# STM32H743V register map
File version: 2.4
CPU: CM7 r0p1, little endian, MPU, FPU, 4 interrupt priority bits
Registers are 32-bit, read-write, reset 0x0 unless marked. A register's access mark holds for its fields unless they carry their own. Offsets are from the block's base; [hi:lo] are bit positions; {n}, {i} and the like mark numbered series; 'fields as' and 'values as' point back to an identical list.

## Ethernet_MAC — Ethernet: media access control (MAC)
Base 0x40028000
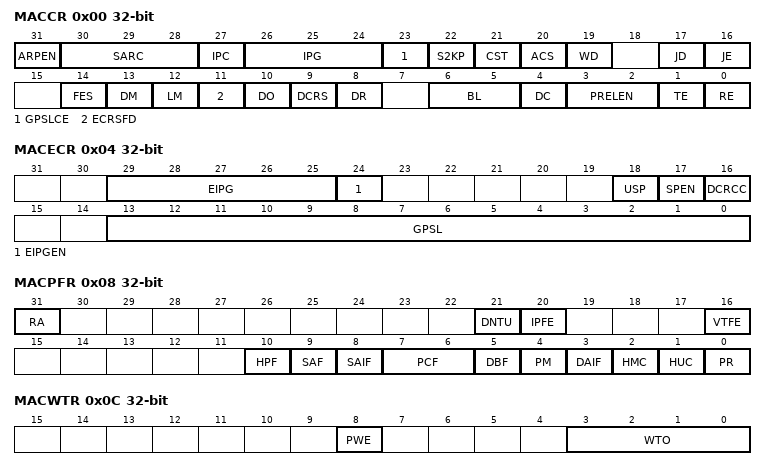
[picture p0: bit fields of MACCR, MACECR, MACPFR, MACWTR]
0x00 MACCR — Operating mode configuration register
  [31] ARPEN — ARP Offload Enable
  [30:28] SARC — Source Address Insertion or Replacement Control
  [27] IPC — Checksum Offload
  [26:24] IPG — Inter-Packet Gap
  [23] GPSLCE — Giant Packet Size Limit Control Enable
  [22] S2KP — IEEE 802.3as Support for 2K Packets
  [21] CST — CRC stripping for Type packets
  [20] ACS — Automatic Pad or CRC Stripping
  [19] WD — Watchdog Disable
  [17] JD — Jabber Disable
  [16] JE — Jumbo Packet Enable
  [14] FES — MAC Speed
  [13] DM — Duplex Mode
  [12] LM — Loopback Mode
  [11] ECRSFD — Enable Carrier Sense Before Transmission in Full-Duplex Mode
  [10] DO — Disable Receive Own
  [9] DCRS — Disable Carrier Sense During Transmission
  [8] DR — Disable Retry
  [6:5] BL — Back-Off Limit
  [4] DC — Deferral Check
  [3:2] PRELEN — Preamble Length for Transmit Packets
  [1] TE — Transmitter Enable
  [0] RE — Receiver Enable
0x04 MACECR — Extended operating mode configuration register
  [29:25] EIPG — Extended Inter-Packet Gap
  [24] EIPGEN — Extended Inter-Packet Gap Enable
  [18] USP — Unicast Slow Protocol Packet Detect
  [17] SPEN — Slow Protocol Detection Enable
  [16] DCRCC — Disable CRC Checking for Received Packets
  [13:0] GPSL — Giant Packet Size Limit
0x08 MACPFR — Packet filtering control register
  [31] RA — Receive All
  [21] DNTU — Drop Non-TCP/UDP over IP Packets
  [20] IPFE — Layer 3 and Layer 4 Filter Enable
  [16] VTFE — VLAN Tag Filter Enable
  [10] HPF — Hash or Perfect Filter
  [9] SAF — Source Address Filter Enable
  [8] SAIF — SA Inverse Filtering
  [7:6] PCF — Pass Control Packets
  [5] DBF — Disable Broadcast Packets
  [4] PM — Pass All Multicast
  [3] DAIF — DA Inverse Filtering
  [2] HMC — Hash Multicast
  [1] HUC — Hash Unicast
  [0] PR — Promiscuous Mode
0x0C MACWTR — Watchdog timeout register
  [8] PWE — Programmable Watchdog Enable
  [3:0] WTO — Watchdog Timeout
0x10 MACHT0R — Hash Table 0 register
  [31:0] HT31T0 — MAC Hash Table First 32 Bits
0x14 MACHT1R — Hash Table 1 register
  [31:0] HT63T32 — MAC Hash Table Second 32 Bits
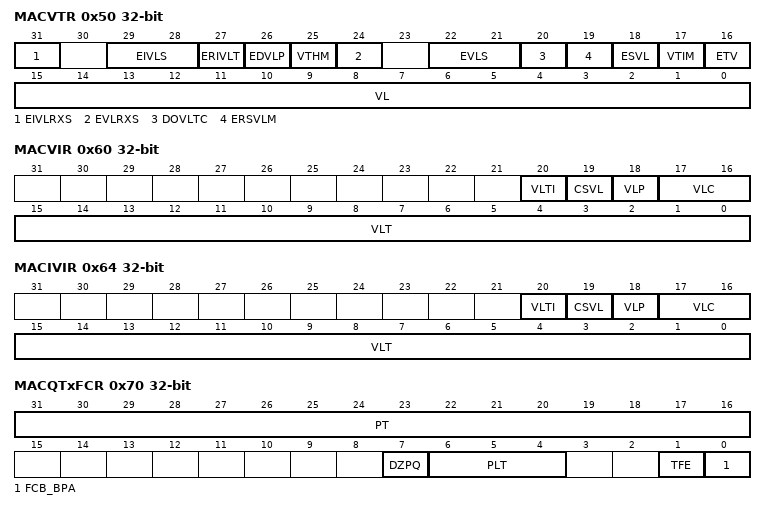
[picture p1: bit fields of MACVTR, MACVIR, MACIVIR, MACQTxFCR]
0x50 MACVTR — VLAN tag register
  [31] EIVLRXS — Enable Inner VLAN Tag in Rx Status
  [29:28] EIVLS — Enable Inner VLAN Tag Stripping on Receive
  [27] ERIVLT — Enable Inner VLAN Tag
  [26] EDVLP — Enable Double VLAN Processing
  [25] VTHM — VLAN Tag Hash Table Match Enable
  [24] EVLRXS — Enable VLAN Tag in Rx status
  [22:21] EVLS — Enable VLAN Tag Stripping on Receive
  [20] DOVLTC — Disable VLAN Type Check
  [19] ERSVLM — Enable Receive S-VLAN Match
  [18] ESVL — Enable S-VLAN
  [17] VTIM — VLAN Tag Inverse Match Enable
  [16] ETV — Enable 12-Bit VLAN Tag Comparison
  [15:0] VL — VLAN Tag Identifier for Receive Packets
0x58 MACVHTR — VLAN Hash table register
  [15:0] VLHT — VLAN Hash Table
0x60 MACVIR — VLAN inclusion register
  [20] VLTI — VLAN Tag Input
  [19] CSVL — C-VLAN or S-VLAN
  [18] VLP — VLAN Priority Control
  [17:16] VLC — VLAN Tag Control in Transmit Packets
  [15:0] VLT — VLAN Tag for Transmit Packets
0x64 MACIVIR — Inner VLAN inclusion register
  fields as MACVIR
0x70 MACQTxFCR — Tx Queue flow control register
  [31:16] PT — Pause Time
  [7] DZPQ — Disable Zero-Quanta Pause
  [6:4] PLT — Pause Low Threshold
  [1] TFE — Transmit Flow Control Enable
  [0] FCB_BPA — Flow Control Busy or Backpressure Activate
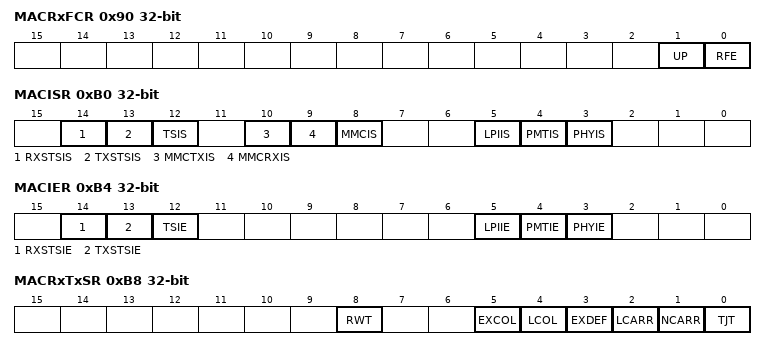
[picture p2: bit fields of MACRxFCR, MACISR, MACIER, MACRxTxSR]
0x90 MACRxFCR — Rx flow control register
  [1] UP — Unicast Pause Packet Detect
  [0] RFE — Receive Flow Control Enable
0xB0 MACISR ro — Interrupt status register
  [14] RXSTSIS — Receive Status Interrupt
  [13] TXSTSIS — Transmit Status Interrupt
  [12] TSIS — Timestamp Interrupt Status
  [10] MMCTXIS — MMC Transmit Interrupt Status
  [9] MMCRXIS — MMC Receive Interrupt Status
  [8] MMCIS — MMC Interrupt Status
  [5] LPIIS — LPI Interrupt Status
  [4] PMTIS — PMT Interrupt Status
  [3] PHYIS — PHY Interrupt
0xB4 MACIER — Interrupt enable register
  [14] RXSTSIE — Receive Status Interrupt Enable
  [13] TXSTSIE — Transmit Status Interrupt Enable
  [12] TSIE — Timestamp Interrupt Enable
  [5] LPIIE — LPI Interrupt Enable
  [4] PMTIE — PMT Interrupt Enable
  [3] PHYIE — PHY Interrupt Enable
0xB8 MACRxTxSR ro — Rx Tx status register
  [8] RWT — Receive Watchdog Timeout
  [5] EXCOL — Excessive Collisions
  [4] LCOL — Late Collision
  [3] EXDEF — Excessive Deferral
  [2] LCARR — Loss of Carrier
  [1] NCARR — No Carrier
  [0] TJT — Transmit Jabber Timeout
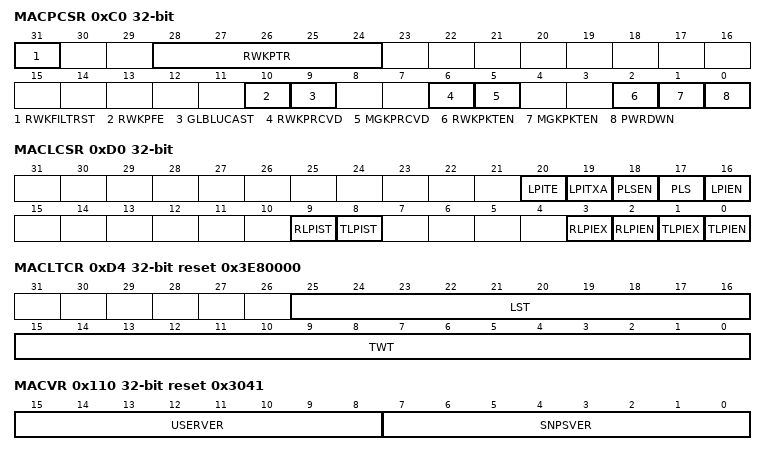
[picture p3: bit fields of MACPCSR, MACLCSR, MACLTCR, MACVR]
0xC0 MACPCSR access per field — PMT control status register
  [31] RWKFILTRST rw — Remote wakeup Packet Filter Register Pointer Reset
  [28:24] RWKPTR rw — Remote wakeup FIFO Pointer
  [10] RWKPFE rw — Remote wakeup Packet Forwarding Enable
  [9] GLBLUCAST rw — Global Unicast
  [6] RWKPRCVD ro — Remote wakeup Packet Received
  [5] MGKPRCVD ro — Magic Packet Received
  [2] RWKPKTEN rw — Remote wakeup Packet Enable
  [1] MGKPKTEN rw — Magic Packet Enable
  [0] PWRDWN rw — Power Down
0xC4 MACRWKPFR — Remove wakeup packet filter register
  [31:0] MACRWKPFR — Remote wakeup packet filter
0xD0 MACLCSR access per field — LPI control status register
  [20] LPITE rw — LPI Timer Enable
  [19] LPITXA rw — LPI Tx Automate
  [18] PLSEN rw — PHY Link Status Enable
  [17] PLS rw — PHY Link Status
  [16] LPIEN rw — LPI Enable
  [9] RLPIST ro — Receive LPI State
  [8] TLPIST ro — Transmit LPI State
  [3] RLPIEX ro — Receive LPI Exit
  [2] RLPIEN ro — Receive LPI Entry
  [1] TLPIEX ro — Transmit LPI Exit
  [0] TLPIEN ro — Transmit LPI Entry
0xD4 MACLTCR reset 0x3E80000 — LPI timers control register
  [25:16] LST — LPI LS Timer
  [15:0] TWT — LPI TW Timer
0xD8 MACLETR — LPI entry timer register
  [19:3] LPIET — LPI Entry Timer
0xDC MAC1USTCR — 1-microsecond-tick counter register
  [11:0] TIC_1US_CNTR — 1 µs tick Counter
0x110 MACVR ro reset 0x3041 — Version register
  [15:8] USERVER — ST-defined version
  [7:0] SNPSVER — IP version
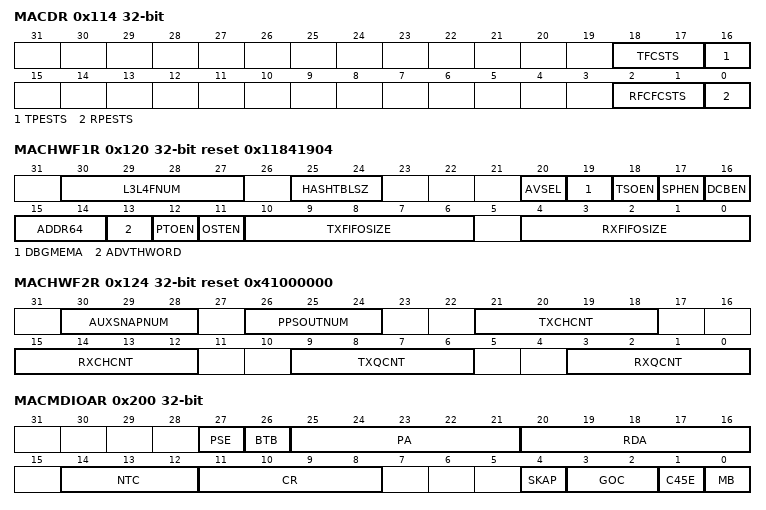
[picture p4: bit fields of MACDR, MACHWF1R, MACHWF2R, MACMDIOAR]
0x114 MACDR ro — Debug register
  [18:17] TFCSTS — MAC Transmit Packet Controller Status
  [16] TPESTS — MAC MII Transmit Protocol Engine Status
  [2:1] RFCFCSTS — MAC Receive Packet Controller FIFO Status
  [0] RPESTS — MAC MII Receive Protocol Engine Status
0x120 MACHWF1R ro reset 0x11841904 — HW feature 1 register
  [30:27] L3L4FNUM — Total number of L3 or L4 Filters
  [25:24] HASHTBLSZ — Hash Table Size
  [20] AVSEL — AV Feature Enable
  [19] DBGMEMA — DMA Debug Registers Enable
  [18] TSOEN — TCP Segmentation Offload Enable
  [17] SPHEN — Split Header Feature Enable
  [16] DCBEN — DCB Feature Enable
  [15:14] ADDR64 — Address width
  [13] ADVTHWORD — IEEE 1588 High Word Register Enable
  [12] PTOEN — PTP Offload Enable
  [11] OSTEN — One-Step Timestamping Enable
  [10:6] TXFIFOSIZE — MTL Transmit FIFO Size
  [4:0] RXFIFOSIZE — MTL Receive FIFO Size
0x124 MACHWF2R ro reset 0x41000000 — HW feature 2 register
  [30:28] AUXSNAPNUM — Number of Auxiliary Snapshot Inputs
  [26:24] PPSOUTNUM — Number of PPS Outputs
  [21:18] TXCHCNT — Number of DMA Transmit Channels
  [15:12] RXCHCNT — Number of DMA Receive Channels
  [9:6] TXQCNT — Number of MTL Transmit Queues
  [3:0] RXQCNT — Number of MTL Receive Queues
0x200 MACMDIOAR — MDIO address register
  [27] PSE — Preamble Suppression Enable
  [26] BTB — Back to Back transactions
  [25:21] PA — Physical Layer Address
  [20:16] RDA — Register/Device Address
  [14:12] NTC — Number of Training Clocks
  [11:8] CR — CSR Clock Range
  [4] SKAP — Skip Address Packet
  [3:2] GOC — MII Operation Command
  [1] C45E — Clause 45 PHY Enable
  [0] MB — MII Busy
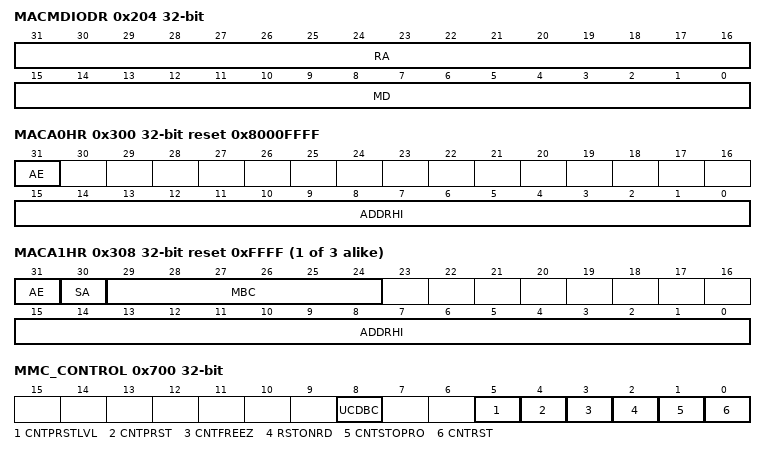
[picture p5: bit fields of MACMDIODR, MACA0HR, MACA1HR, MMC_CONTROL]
0x204 MACMDIODR — MDIO data register
  [31:16] RA — Register Address
  [15:0] MD — MII Data
0x300 MACA0HR access per field reset 0x8000FFFF — Address 0 high register
  [31] AE ro — Address Enable
  [15:0] ADDRHI rw — MAC Address0[47:32]
{0x304+8i} MACA{i}LR reset 0xFFFFFFFF (i=0..3) — Address {i} low register
  [31:0] ADDRLO — MAC Address {i} [31:0]
{0x300+8i} MACA{i}HR reset 0xFFFF (i=1..3) — Address {i} high register
  [31] AE — Address Enable
  [30] SA — Source Address
  [29:24] MBC — Mask Byte Control
  [15:0] ADDRHI — MAC Address{i} [47:32]
0x700 MMC_CONTROL
  [8] UCDBC — Update MMC Counters for Dropped Broadcast Packets
  [5] CNTPRSTLVL — Full-Half Preset
  [4] CNTPRST — Counters Preset
  [3] CNTFREEZ — MMC Counter Freeze
  [2] RSTONRD — Reset on Read
  [1] CNTSTOPRO — Counter Stop Rollover
  [0] CNTRST — Counters Reset
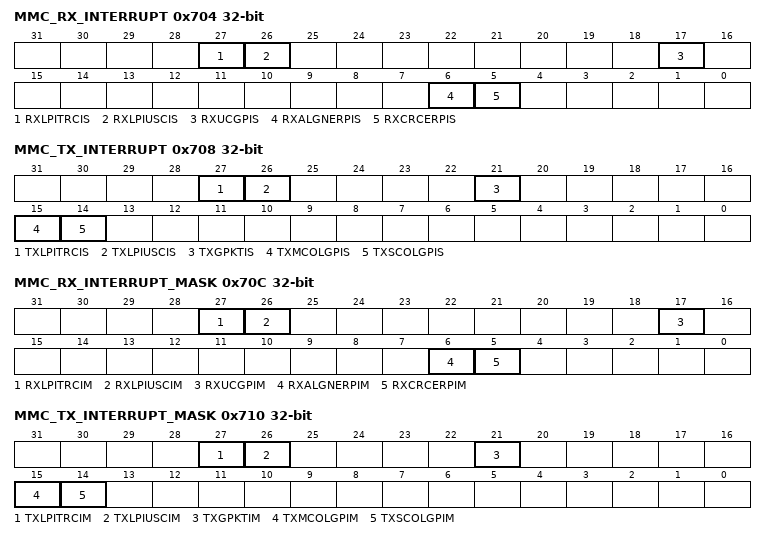
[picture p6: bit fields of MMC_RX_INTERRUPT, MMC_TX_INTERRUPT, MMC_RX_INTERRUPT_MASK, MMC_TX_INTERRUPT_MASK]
0x704 MMC_RX_INTERRUPT ro
  [27] RXLPITRCIS — MMC Receive LPI transition counter interrupt status
  [26] RXLPIUSCIS — MMC Receive LPI microsecond counter interrupt status
  [17] RXUCGPIS — MMC Receive Unicast Good Packet Counter Interrupt Status
  [6] RXALGNERPIS — MMC Receive Alignment Error Packet Counter Interrupt Status
  [5] RXCRCERPIS — MMC Receive CRC Error Packet Counter Interrupt Status
0x708 MMC_TX_INTERRUPT ro
  [27] TXLPITRCIS — MMC Transmit LPI transition counter interrupt status
  [26] TXLPIUSCIS — MMC Transmit LPI microsecond counter interrupt status
  [21] TXGPKTIS — MMC Transmit Good Packet Counter Interrupt Status
  [15] TXMCOLGPIS — MMC Transmit Multiple Collision Good Packet Counter Interrupt Status
  [14] TXSCOLGPIS — MMC Transmit Single Collision Good Packet Counter Interrupt Status
0x70C MMC_RX_INTERRUPT_MASK
  [27] RXLPITRCIM — MMC Receive LPI transition counter interrupt Mask
  [26] RXLPIUSCIM — MMC Receive LPI microsecond counter interrupt Mask
  [17] RXUCGPIM — MMC Receive Unicast Good Packet Counter Interrupt Mask
  [6] RXALGNERPIM — MMC Receive Alignment Error Packet Counter Interrupt Mask
  [5] RXCRCERPIM — MMC Receive CRC Error Packet Counter Interrupt Mask
0x710 MMC_TX_INTERRUPT_MASK
  [27] TXLPITRCIM — MMC Transmit LPI transition counter interrupt Mask
  [26] TXLPIUSCIM — MMC Transmit LPI microsecond counter interrupt Mask
  [21] TXGPKTIM — MMC Transmit Good Packet Counter Interrupt Mask
  [15] TXMCOLGPIM — MMC Transmit Multiple Collision Good Packet Counter Interrupt Mask
  [14] TXSCOLGPIM — MMC Transmit Single Collision Good Packet Counter Interrupt Mask
0x74C TX_SINGLE_COLLISION_GOOD_PACKETS ro
  [31:0] TXSNGLCOLG — Tx Single Collision Good Packets
0x750 TX_MULTIPLE_COLLISION_GOOD_PACKETS ro
  [31:0] TXMULTCOLG — Tx Multiple Collision Good Packets
0x768 TX_PACKET_COUNT_GOOD ro
  [31:0] TXPKTG — Tx Packet Count Good
0x794 RX_CRC_ERROR_PACKETS ro
  [31:0] RXCRCERR — Rx CRC Error Packets
0x798 RX_ALIGNMENT_ERROR_PACKETS ro
  [31:0] RXALGNERR — Rx Alignment Error Packets
0x7C4 RX_UNICAST_PACKETS_GOOD ro
  [31:0] RXUCASTG — Rx Unicast Packets Good
0x7EC TX_LPI_USEC_CNTR ro — Tx LPI microsecond timer register
  [31:0] TXLPIUSC — Tx LPI Microseconds Counter
0x7F0 TX_LPI_TRAN_CNTR ro — Tx LPI transition counter register
  [31:0] TXLPITRC — Tx LPI Transition counter
0x7F4 RX_LPI_USEC_CNTR ro — Rx LPI microsecond counter register
  [31:0] RXLPIUSC — Rx LPI Microseconds Counter
0x7F8 RX_LPI_TRAN_CNTR ro — Rx LPI transition counter register
  [31:0] RXLPITRC — Rx LPI Transition counter
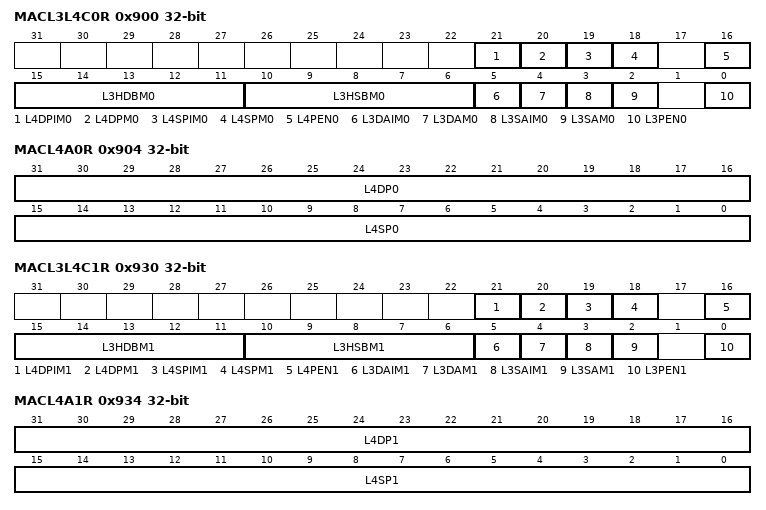
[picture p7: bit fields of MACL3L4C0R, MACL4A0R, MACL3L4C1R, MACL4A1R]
0x900 MACL3L4C0R — L3 and L4 control 0 register
  [21] L4DPIM0 — Layer 4 Destination Port Inverse Match Enable
  [20] L4DPM0 — Layer 4 Destination Port Match Enable
  [19] L4SPIM0 — Layer 4 Source Port Inverse Match Enable
  [18] L4SPM0 — Layer 4 Source Port Match Enable
  [16] L4PEN0 — Layer 4 Protocol Enable
  [15:11] L3HDBM0 — Layer 3 IP DA Higher Bits Match
  [10:6] L3HSBM0 — Layer 3 IP SA Higher Bits Match
  [5] L3DAIM0 — Layer 3 IP DA Inverse Match Enable
  [4] L3DAM0 — Layer 3 IP DA Match Enable
  [3] L3SAIM0 — Layer 3 IP SA Inverse Match Enable
  [2] L3SAM0 — Layer 3 IP SA Match Enable
  [0] L3PEN0 — Layer 3 Protocol Enable
0x904 MACL4A0R — Layer4 address filter 0 register
  [31:16] L4DP0 — Layer 4 Destination Port Number Field
  [15:0] L4SP0 — Layer 4 Source Port Number Field
0x910 MACL3A00R
  [31:0] L3A00 — Layer 3 Address 0 Field
0x914 MACL3A10R — Layer3 address 1 filter 0 register
  [31:0] L3A10 — Layer 3 Address 1 Field
0x918 MACL3A20 — Layer3 Address 2 filter 0 register
  [31:0] L3A20 — Layer 3 Address 2 Field
0x91C MACL3A30 — Layer3 Address 3 filter 0 register
  [31:0] L3A30 — Layer 3 Address 3 Field
0x930 MACL3L4C1R — L3 and L4 control 1 register
  [21] L4DPIM1 — Layer 4 Destination Port Inverse Match Enable
  [20] L4DPM1 — Layer 4 Destination Port Match Enable
  [19] L4SPIM1 — Layer 4 Source Port Inverse Match Enable
  [18] L4SPM1 — Layer 4 Source Port Match Enable
  [16] L4PEN1 — Layer 4 Protocol Enable
  [15:11] L3HDBM1 — Layer 3 IP DA Higher Bits Match
  [10:6] L3HSBM1 — Layer 3 IP SA Higher Bits Match
  [5] L3DAIM1 — Layer 3 IP DA Inverse Match Enable
  [4] L3DAM1 — Layer 3 IP DA Match Enable
  [3] L3SAIM1 — Layer 3 IP SA Inverse Match Enable
  [2] L3SAM1 — Layer 3 IP SA Match Enable
  [0] L3PEN1 — Layer 3 Protocol Enable
0x934 MACL4A1R — Layer 4 address filter 1 register
  [31:16] L4DP1 — Layer 4 Destination Port Number Field
  [15:0] L4SP1 — Layer 4 Source Port Number Field
0x940 MACL3A01R — Layer3 address 0 filter 1 Register
  [31:0] L3A01 — Layer 3 Address 0 Field
0x944 MACL3A11R — Layer3 address 1 filter 1 register
  [31:0] L3A11 — Layer 3 Address 1 Field
0x948 MACL3A21R — Layer3 address 2 filter 1 Register
  [31:0] L3A21 — Layer 3 Address 2 Field
0x94C MACL3A31R — Layer3 address 3 filter 1 register
  [31:0] L3A31 — Layer 3 Address 3 Field
0xAE0 MACARPAR — ARP address register
  [31:0] ARPPA — ARP Protocol Address
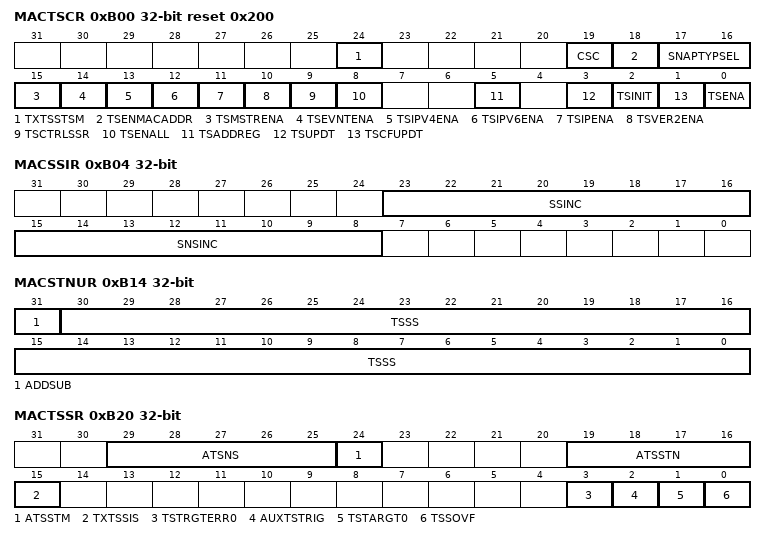
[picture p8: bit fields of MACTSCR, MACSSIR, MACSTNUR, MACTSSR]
0xB00 MACTSCR access per field reset 0x200 — Timestamp control Register
  [24] TXTSSTSM rw — Transmit Timestamp Status Mode
  [19] CSC ro — Enable checksum correction during OST for PTP over UDP/IPv4 packets
  [18] TSENMACADDR rw — Enable MAC Address for PTP Packet Filtering
  [17:16] SNAPTYPSEL rw — Select PTP packets for Taking Snapshots
  [15] TSMSTRENA rw — Enable Snapshot for Messages Relevant to Master
  [14] TSEVNTENA rw — Enable Timestamp Snapshot for Event Messages
  [13] TSIPV4ENA rw — Enable Processing of PTP Packets Sent over IPv4-UDP
  [12] TSIPV6ENA rw — Enable Processing of PTP Packets Sent over IPv6-UDP
  [11] TSIPENA rw — Enable Processing of PTP over Ethernet Packets
  [10] TSVER2ENA rw — Enable PTP Packet Processing for Version 2 Format
  [9] TSCTRLSSR rw — Timestamp Digital or Binary Rollover Control
  [8] TSENALL rw — Enable Timestamp for All Packets
  [5] TSADDREG rw — Update Addend Register
  [3] TSUPDT rw — Update Timestamp
  [2] TSINIT rw — Initialize Timestamp
  [1] TSCFUPDT rw — Fine or Coarse Timestamp Update
  [0] TSENA rw — Enable Timestamp
0xB04 MACSSIR — Sub-second increment register
  [23:16] SSINC — Sub-second Increment Value
  [15:8] SNSINC — Sub-nanosecond Increment Value
0xB08 MACSTSR ro — System time seconds register
  [31:0] TSS — Timestamp Second
0xB0C MACSTNR ro — System time nanoseconds register
  [30:0] TSSS — Timestamp Sub-seconds
0xB10 MACSTSUR — System time seconds update register
  [31:0] TSS — Timestamp Seconds
0xB14 MACSTNUR — System time nanoseconds update register
  [31] ADDSUB — Add or Subtract Time
  [30:0] TSSS — Timestamp Sub-seconds
0xB18 MACTSAR — Timestamp addend register
  [31:0] TSAR — Timestamp Addend Register
0xB20 MACTSSR ro — Timestamp status register
  [29:25] ATSNS — Number of Auxiliary Timestamp Snapshots
  [24] ATSSTM — Auxiliary Timestamp Snapshot Trigger Missed
  [19:16] ATSSTN — Auxiliary Timestamp Snapshot Trigger Identifier
  [15] TXTSSIS — Tx Timestamp Status Interrupt Status
  [3] TSTRGTERR0 — Timestamp Target Time Error
  [2] AUXTSTRIG — Auxiliary Timestamp Trigger Snapshot
  [1] TSTARGT0 — Timestamp Target Time Reached
  [0] TSSOVF — Timestamp Seconds Overflow
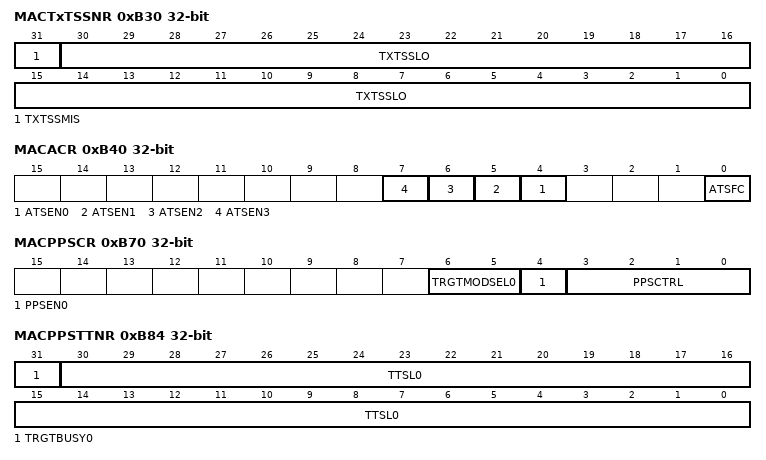
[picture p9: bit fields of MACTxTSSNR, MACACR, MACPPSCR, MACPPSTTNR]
0xB30 MACTxTSSNR ro — Tx timestamp status nanoseconds register
  [31] TXTSSMIS — Transmit Timestamp Status Missed
  [30:0] TXTSSLO — Transmit Timestamp Status Low
0xB34 MACTxTSSSR ro — Tx timestamp status seconds register
  [31:0] TXTSSHI — Transmit Timestamp Status High
0xB40 MACACR — Auxiliary control register
  [n+4] ATSEN{n} (n=0..3) — Auxiliary Snapshot {n} Enable
  [0] ATSFC — Auxiliary Snapshot FIFO Clear
0xB48 MACATSNR ro — Auxiliary timestamp nanoseconds register
  [30:0] AUXTSLO — Auxiliary Timestamp
0xB4C MACATSSR ro — Auxiliary timestamp seconds register
  [31:0] AUXTSHI — Auxiliary Timestamp
0xB50 MACTSIACR — Timestamp Ingress asymmetric correction register
  [31:0] OSTIAC — One-Step Timestamp Ingress Asymmetry Correction
0xB54 MACTSEACR — Timestamp Egress asymmetric correction register
  [31:0] OSTEAC — One-Step Timestamp Egress Asymmetry Correction
0xB58 MACTSICNR — Timestamp Ingress correction nanosecond register
  [31:0] TSIC — Timestamp Ingress Correction
0xB5C MACTSECNR — Timestamp Egress correction nanosecond register
  [31:0] TSEC — Timestamp Egress Correction
0xB70 MACPPSCR — PPS control register
  [6:5] TRGTMODSEL0 — Target Time Register Mode for PPS Output
  [4] PPSEN0 — Flexible PPS Output Mode Enable
  [3:0] PPSCTRL — Flexible PPS Output (ptp_pps_o[0]) Control or PPSCTRL PPS Output Frequency Control if PPSEN0 is cleared
0xB80 MACPPSTTSR — PPS target time seconds register
  [30:0] TSTRH0 — PPS Target Time Seconds Register
0xB84 MACPPSTTNR — PPS target time nanoseconds register
  [31] TRGTBUSY0 — PPS Target Time Register Busy
  [30:0] TTSL0 — Target Time Low for PPS Register
0xB88 MACPPSIR — PPS interval register
  [31:0] PPSINT0 — PPS Output Signal Interval
0xB8C MACPPSWR — PPS width register
  [31:0] PPSWIDTH0 — PPS Output Signal Width
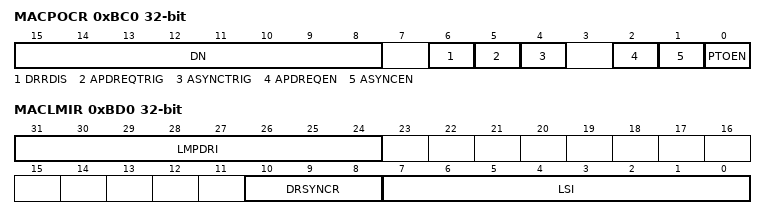
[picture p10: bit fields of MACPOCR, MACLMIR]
0xBC0 MACPOCR — PTP Offload control register
  [15:8] DN — Domain Number
  [6] DRRDIS — Disable PTO Delay Request/Response response generation
  [5] APDREQTRIG — Automatic PTP Pdelay_Req message Trigger
  [4] ASYNCTRIG — Automatic PTP SYNC message Trigger
  [2] APDREQEN — Automatic PTP Pdelay_Req message Enable
  [1] ASYNCEN — Automatic PTP SYNC message Enable
  [0] PTOEN — PTP Offload Enable
0xBC4 MACSPI0R — PTP Source Port Identity 0 Register
  [31:0] SPI0 — Source Port Identity 0
0xBC8 MACSPI1R — PTP Source port identity 1 register
  [31:0] SPI1 — Source Port Identity 1
0xBCC MACSPI2R — PTP Source port identity 2 register
  [15:0] SPI2 — Source Port Identity 2
0xBD0 MACLMIR — Log message interval register
  [31:24] LMPDRI — Log Min Pdelay_Req Interval
  [10:8] DRSYNCR — Delay_Req to SYNC Ratio
  [7:0] LSI — Log Sync Interval
